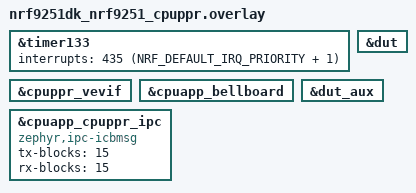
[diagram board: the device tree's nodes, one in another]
/*
 * Copyright (c) 2026 Nordic Semiconductor ASA
 *
 * SPDX-License-Identifier: LicenseRef-Nordic-5-Clause
 */

#include "nrf9251dk_nrf9251_cpuapp.overlay"

&timer133 {
	interrupts = <435 (NRF_DEFAULT_IRQ_PRIORITY + 1)>;
};

&cpuppr_vevif {
	status = "okay";
};

&cpuapp_bellboard {
	status = "okay";
};

ipc0: &cpuapp_cpuppr_ipc {
	status = "okay";
	compatible = "zephyr,ipc-icbmsg";
	tx-blocks = <15>;
	rx-blocks = <15>;
};

&dut {
	/delete-property/ memory-regions;
};

&dut_aux {
	/delete-property/ memory-regions;
};
